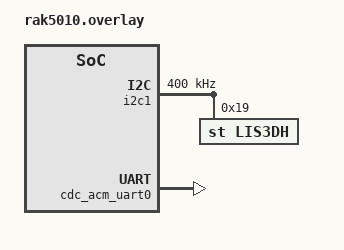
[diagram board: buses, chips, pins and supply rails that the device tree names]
/ {
	chosen {
		zephyr,console = &cdc_acm_uart0;
	};
};

&i2c1 {
	status = "okay";
	clock-frequency = <I2C_BITRATE_FAST>;
	lis3dh: lis3dh@19 {
		compatible = "st,lis3dh", "st,lis2dh";
		reg = <0x19>;
	};
};

&zephyr_udc0 {
	cdc_acm_uart0: cdc_acm_uart0 {
		compatible = "zephyr,cdc-acm-uart";
	};
};
